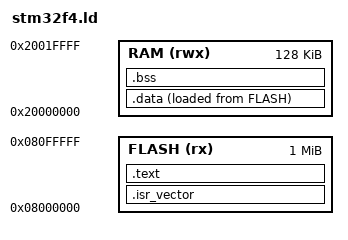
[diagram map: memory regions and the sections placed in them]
/* STM32F4 Linker Script */

MEMORY
{
    FLASH (rx) : ORIGIN = 0x08000000, LENGTH = 1024K
    RAM (rwx)  : ORIGIN = 0x20000000, LENGTH = 128K
}

/* Entry Point */
ENTRY(Reset_Handler)

/* Highest address of the stack */
_estack = ORIGIN(RAM) + LENGTH(RAM);

SECTIONS
{
    /* Interrupt vector table at the start of FLASH */
    .isr_vector :
    {
        . = ALIGN(4);
        KEEP(*(.isr_vector))
        . = ALIGN(4);
    } >FLASH

    /* The program code and other data */
    .text :
    {
        . = ALIGN(4);
        *(.text)
        *(.text*)
        *(.rodata)
        *(.rodata*)
        . = ALIGN(4);
        _etext = .;
    } >FLASH

    /* Initialized data */
    _sidata = LOADADDR(.data);
    .data :
    {
        _sdata = .;
        *(.data)
        *(.data*)
        . = ALIGN(4);
        _edata = .;
    } >RAM AT>FLASH

    /* Uninitialized data section */
    .bss :
    {
        _sbss = .;
        *(.bss)
        *(.bss*)
        *(COMMON)
        . = ALIGN(4);
        _ebss = .;
    } >RAM

    /* Remove information from the standard libraries */
    /DISCARD/ :
    {
        libc.a ( * )
        libm.a ( * )
        libgcc.a ( * )
    }
} 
